# USB_USB2SS_LINK_3100D000h register map
Vendor: Texas Instruments
Peripheral module from a debugger description file (folder am62L).
Registers are 32-bit, read-write, reset values left out (the file's numbers can be read two ways) unless marked. A register's access mark holds for its fields unless they carry their own. Offsets are as the file gives them; lines under a group give offsets from that group; [hi:lo] are bit positions; {n}, {i} and the like mark numbered series; 'fields as' and 'values as' point back to an identical list; <NAME> marks a mode.

## USB2SS_LINK
0x00 USB2SS_LINK_LINK access not given
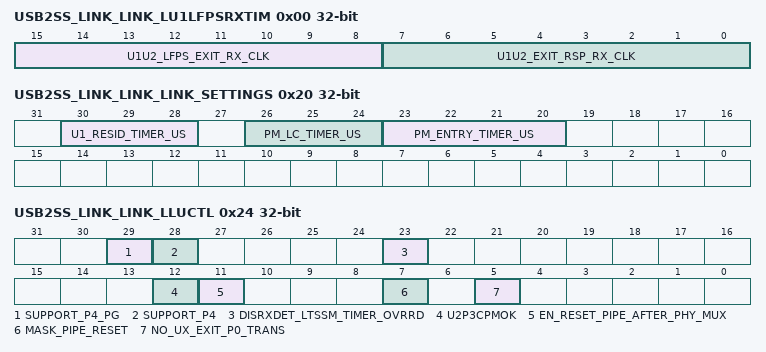
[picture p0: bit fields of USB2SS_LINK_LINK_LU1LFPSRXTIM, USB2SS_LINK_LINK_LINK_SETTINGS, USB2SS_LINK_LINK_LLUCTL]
0x00 USB2SS_LINK_LINK_LU1LFPSRXTIM — U1/U2 LFPS Rx Timer Register - Link Layer Register for U1/U2 LFPS RX Timers. - This register is common for all SS ports.
  [15:8] U1U2_LFPS_EXIT_RX_CLK — Programmable U1U2 LFPS EXIT RX CLKS - Applicable to Remote Partner initiated Ux exit: Time to recognize valid Ux exit request from the remote partner. - This field is encoded as the pipe clk [8ns] count for the LFPS. -- 1: 8ns -- 2: 16ns -- 3: 24ns, and so on Reset Source: rst_mod_g_rst_n
  [7:0] U1U2_EXIT_RSP_RX_CLK — Programmable U1U2 EXIT RESP RX CLKS - Applicable to locally initiated Ux exit: Minimum LFPS reception from remote to consider Ux exit handshake is successful. - This field is encoded as the pipe clk [8ns] count for the LFPS. -- 1: 8ns -- 2: 16ns -- 3: 24ns, and so on Reset Source: rst_mod_g_rst_n
0x20 USB2SS_LINK_LINK_LINK_SETTINGS — Link Setting Register - Link Layer User Control Register for enabling Link/PHY-specific options. - This register is common for all SS ports.
  [30:28] U1_RESID_TIMER_US — Programmable U1 MIN RESIDENCY TIMERThis field specifies U1 MIN RESIDENCY TIMER value in us. Set to 0 to disable the timer. Reset Source: rst_mod_g_rst_n
  [26:24] PM_LC_TIMER_US — Programmable PM_LC_TIMERThis field specifies PM_LC_TIMER value in us. Reset Source: rst_mod_g_rst_n
  [23:20] PM_ENTRY_TIMER_US — Programmable PM_ENTRY_TIMERThis field specifies PM_ENTRY_TIMER value in us. Reset Source: rst_mod_g_rst_n
0x24 USB2SS_LINK_LINK_LLUCTL — Link User Control Register - Link Layer User Control Register for enabling Link/PHY-specific options. - This register is common for all SS ports.
  [29] SUPPORT_P4_PG — PHY P4 Power gate mode [PG] is enabled.Set this bit if the PHY supports PG mode in P4. This bit is used only for Synopsys PHY. Reset Source: rst_mod_g_rst_n
  [28] SUPPORT_P4 — Support PHY P3.CPM and P4 Power States.When this bit is set, the controller puts the PHY in P3.CPM or P4 in certain states. This bit is used only for Synopsys PHY. Reset Source: rst_mod_g_rst_n
  [23] DISRXDET_LTSSM_TIMER_OVRRD — DisRxDet_LTSSM_Timer_Ovrrd.When DisRxDetU3RxDet is asserted in Polling or U1, the timeout expires immediately. Reset Source: rst_mod_g_rst_n
  [12] U2P3CPMOK — P3CPM OK for U2/SSInactive [U2P3CPMok] - 0: During link state U2/SS.Inactive, put PHY in P2 [Default] - 1: During link state U2/SS.Inactive, put PHY in P3CPM.Note: For a port, if both GUCTL1[25]=1 and LUCTL[12]=1, LUCTL[12]=1 takes priority. Reset Source: rst_mod_g_rst_n
  [11] EN_RESET_PIPE_AFTER_PHY_MUX — en_reset_pipe_after_phy_mux.The controller issues USB 3.0 PHY reset after DisRxDetU3RxDet is de-asserted. Reset Source: rst_mod_g_rst_n
  [7] MASK_PIPE_RESET — Mask pipe reset.If this bit is set, controller blocks pipe_reset_n from going to the PHY when DisRxDetU3RxDet=1. Reset Source: rst_mod_g_rst_n
  [5] NO_UX_EXIT_P0_TRANS — no_ux_exit_p0_trans.Link LTSSM detects Ux_exit LFPS when P0 transition is on-going by default. If this bit is set, Link LTSSM may miss Ux_exit LFPS when P0 transition is happening. Reset Source: rst_mod_g_rst_n
0x28 USB2SS_LINK_LINK_LPTMDPDELAY — Link Datapath Delay Register - Link Layer Timer Register for P3CPM/P4 Residency. - This register is common for all SS ports.
  [21:10] P3CPMP4_RESIDENCY — p3cpmp4 residency timer value.Minimum number of suspend_clk periods that the controller needs to stay in P3.CPM or P4 before exiting P3.CPM or P4. This field is used only for Synopsys PHY. Reset Source: rst_mod_g_rst_n
